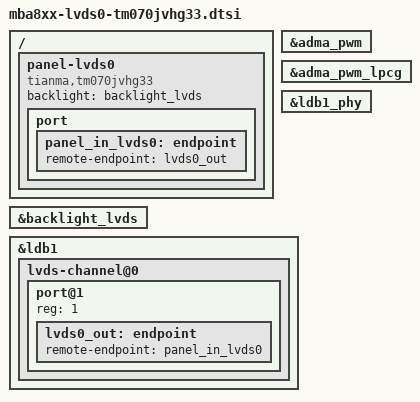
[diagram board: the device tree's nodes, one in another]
// SPDX-License-Identifier: (GPL-2.0-or-later OR MIT)
/*
 * Copyright 2021-2022 TQ-Systems GmbH
 * Author: Alexander Stein <linux@ew.tq-group.com>
 */

/ {
	panel-lvds0 {
		compatible = "tianma,tm070jvhg33";
		backlight = <&backlight_lvds>;
		status = "okay";

		port {
			panel_in_lvds0: endpoint {
				remote-endpoint = <&lvds0_out>;
			};
		};
	};
};

&adma_pwm {
	status = "okay";
};

&adma_pwm_lpcg {
	status = "okay";
};

&backlight_lvds {
	status = "okay";
};

&ldb1_phy {
	status = "okay";
};

&ldb1 {
	status = "okay";

	lvds-channel@0 {
		status = "okay";

		port@1 {
			reg = <1>;

			lvds0_out: endpoint {
				remote-endpoint = <&panel_in_lvds0>;
			};
		};
	};
};
